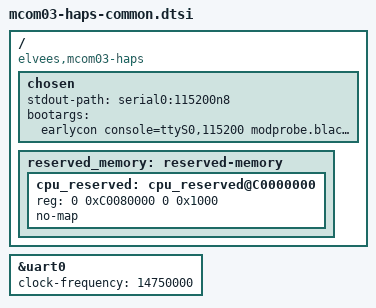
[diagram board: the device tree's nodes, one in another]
// SPDX-License-Identifier: GPL-2.0+
/*
 * Copyright 2019 RnD Center "ELVEES", JSC
 */

/dts-v1/;

#include "mcom03.dtsi"

/ {
	compatible = "elvees,mcom03-haps";

	chosen {
		stdout-path = "serial0:115200n8";
		bootargs = "earlycon console=ttyS0,115200 modprobe.blacklist=acptest,vdmaacptest";
	};

	reserved_memory: reserved-memory {
		#address-cells = <2>;
		#size-cells = <2>;
		ranges;

		cpu_reserved: cpu_reserved@C0000000 {
			reg = <0 0xC0080000 0 0x1000>;
			no-map;
		};
	};
};

&uart0 {
	status = "okay";
	clock-frequency = <14750000>;
};
